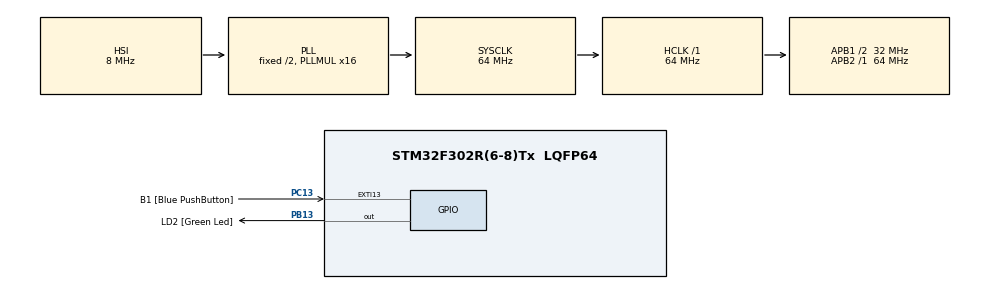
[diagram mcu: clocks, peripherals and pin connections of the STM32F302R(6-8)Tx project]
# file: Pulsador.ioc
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Mcu.Family=STM32F3
Mcu.Name=STM32F302R(6-8)Tx
Mcu.Package=LQFP64
NVIC.PriorityGroup=NVIC_PRIORITYGROUP_0
PB13.GPIO_Label=LD2 [Green Led]
PB13.Signal=GPIO_Output
PC13.GPIO_Label=B1 [Blue PushButton]
PC13.GPIO_ModeDefaultEXTI=GPIO_MODE_IT_FALLING
PC13.Signal=GPXTI13
ProjectManager.HeapSize=0x200
ProjectManager.StackSize=0x400
ProjectManager.TargetToolchain=STM32CubeIDE
RCC.AHBFreq_Value=64000000
RCC.APB1CLKDivider=RCC_HCLK_DIV2
RCC.APB1Freq_Value=32000000
RCC.APB1TimFreq_Value=64000000
RCC.APB2Freq_Value=64000000
RCC.APB2TimFreq_Value=64000000
RCC.CortexFreq_Value=64000000
RCC.HCLKFreq_Value=64000000
RCC.HSE_VALUE=8000000
RCC.HSI_VALUE=8000000
RCC.PLLM=8
RCC.PLLMUL=RCC_PLL_MUL16
RCC.PLLN=336
RCC.PLLP=RCC_PLLP_DIV4
RCC.PLLQ=7
RCC.RCC_PLLsource_Clock_Source_FROM_HSE=RCC_HSE_PREDIV_DIV2
RCC.SYSCLKFreq_VALUE=64000000
RCC.SYSCLKSourceVirtual=RCC_SYSCLKSOURCE_PLLCLK
RCC.USBFreq_Value=64000000
board=NUCLEO-F302R8

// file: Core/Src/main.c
/* USER CODE BEGIN Header */
/**
  ******************************************************************************
  * @file           : main.c
  * @brief          : Main program body
  ******************************************************************************
  * @attention
  *
  * Copyright (c) 2023 STMicroelectronics.
  * All rights reserved.
  *
  * This software is licensed under terms that can be found in the LICENSE file
  * in the root directory of this software component.
  * If no LICENSE file comes with this software, it is provided AS-IS.
  *
  ******************************************************************************
  */
/* USER CODE END Header */
#include "main.h"

/* USER CODE BEGIN Includes */
#include "stdbool.h"
/* USER CODE END Includes */

void SystemClock_Config(void);
static void MX_GPIO_Init(void);

int main(void)
{
  /* USER CODE BEGIN 1 */
GPIO_PinState estpul;
bool ctrl = false;
  /* USER CODE END 1 */

  /* MCU Configuration--------------------------------------------------------*/

  /* Reset of all peripherals, Initializes the Flash interface and the Systick. */
  HAL_Init();

  /* Configure the system clock */
  SystemClock_Config();

  /* Initialize all configured peripherals */
  MX_GPIO_Init();

  /* Infinite loop */
  while (1)
  {

    /* USER CODE BEGIN 3 */
	estpul = HAL_GPIO_ReadPin(GPIOC, GPIO_PIN_13);

	if (estpul && !ctrl){

		ctrl = true;
		HAL_Delay(50);
	}
	else if (!estpul && ctrl){

	HAL_GPIO_TogglePin(GPIOB, GPIO_PIN_13);
	ctrl = false ;
	HAL_Delay(50);
	}

  }
  /* USER CODE END 3 */
}

void SystemClock_Config(void)
{
  RCC_OscInitTypeDef RCC_OscInitStruct = {0};
  RCC_ClkInitTypeDef RCC_ClkInitStruct = {0};

  /** Initializes the RCC Oscillators according to the specified parameters
  * in the RCC_OscInitTypeDef structure.
  */
  RCC_OscInitStruct.OscillatorType = RCC_OSCILLATORTYPE_HSI;
  RCC_OscInitStruct.HSIState = RCC_HSI_ON;
  RCC_OscInitStruct.HSICalibrationValue = RCC_HSICALIBRATION_DEFAULT;
  RCC_OscInitStruct.PLL.PLLState = RCC_PLL_ON;
  RCC_OscInitStruct.PLL.PLLSource = RCC_PLLSOURCE_HSI;
  RCC_OscInitStruct.PLL.PLLMUL = RCC_PLL_MUL16;
  if (HAL_RCC_OscConfig(&RCC_OscInitStruct) != HAL_OK)
  {
    Error_Handler();
  }

  /** Initializes the CPU, AHB and APB buses clocks
  */
  RCC_ClkInitStruct.ClockType = RCC_CLOCKTYPE_HCLK|RCC_CLOCKTYPE_SYSCLK
                              |RCC_CLOCKTYPE_PCLK1|RCC_CLOCKTYPE_PCLK2;
  RCC_ClkInitStruct.SYSCLKSource = RCC_SYSCLKSOURCE_PLLCLK;
  RCC_ClkInitStruct.AHBCLKDivider = RCC_SYSCLK_DIV1;
  RCC_ClkInitStruct.APB1CLKDivider = RCC_HCLK_DIV2;
  RCC_ClkInitStruct.APB2CLKDivider = RCC_HCLK_DIV1;

  if (HAL_RCC_ClockConfig(&RCC_ClkInitStruct, FLASH_LATENCY_2) != HAL_OK)
  {
    Error_Handler();
  }
}

static void MX_GPIO_Init(void)
{
  GPIO_InitTypeDef GPIO_InitStruct = {0};

  /* GPIO Ports Clock Enable */
  __HAL_RCC_GPIOC_CLK_ENABLE();
  __HAL_RCC_GPIOB_CLK_ENABLE();

  /*Configure GPIO pin Output Level */
  HAL_GPIO_WritePin(LD2_GPIO_Port, LD2_Pin, GPIO_PIN_RESET);

  /*Configure GPIO pin : B1_Pin */
  GPIO_InitStruct.Pin = B1_Pin;
  GPIO_InitStruct.Mode = GPIO_MODE_IT_FALLING;
  GPIO_InitStruct.Pull = GPIO_NOPULL;
  HAL_GPIO_Init(B1_GPIO_Port, &GPIO_InitStruct);

  /*Configure GPIO pin : LD2_Pin */
  GPIO_InitStruct.Pin = LD2_Pin;
  GPIO_InitStruct.Mode = GPIO_MODE_OUTPUT_PP;
  GPIO_InitStruct.Pull = GPIO_NOPULL;
  GPIO_InitStruct.Speed = GPIO_SPEED_FREQ_LOW;
  HAL_GPIO_Init(LD2_GPIO_Port, &GPIO_InitStruct);

}

void Error_Handler(void)
{
  __disable_irq();
  while (1)
  {
  }
}
